# ESP32S31_RADIO register map
Vendor: Espressif; Series: ESP32-S31; File version: 3.52
Registers are 32-bit, read-write, no defined reset value unless marked. A register's access mark holds for its fields unless they carry their own. Offsets are from the block's base; [hi:lo] are bit positions; {n}, {i} and the like mark numbered series.

## SYSTIMER — The system timer's comparators: their enables in CONF, targets, modes, load strobes and interrupt enables; their acknowledgements are SYSTIMER_ACKNOWLEDGE. The counter latch of unit zero is the separate shared block SYSTIMER_COUNTER; unit one, the unit loads and the read-back registers are not described.
Base 0x20399000
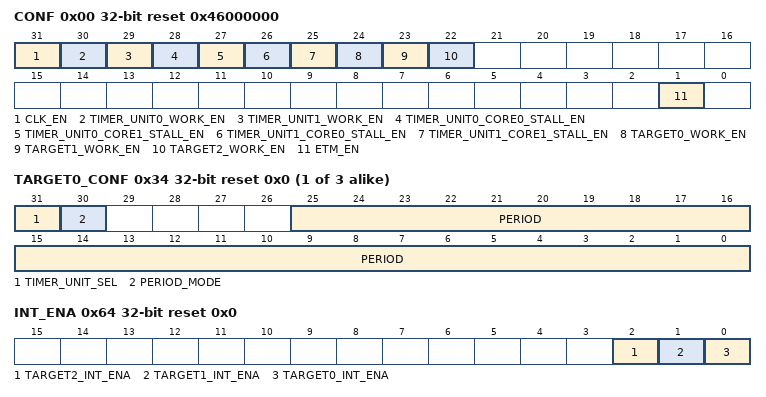
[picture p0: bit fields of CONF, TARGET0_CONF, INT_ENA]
0x00 CONF reset 0x46000000 — Project-assigned name. Clock, unit and comparator enables.
  [31] CLK_EN — Project-assigned name. Keeps the register clock enabled for every access.
  [30] TIMER_UNIT0_WORK_EN — Project-assigned name. Enables unit 0.
  [29] TIMER_UNIT1_WORK_EN — Project-assigned name. Enables unit 1.
  [28] TIMER_UNIT0_CORE0_STALL_EN — Project-assigned name. Stalls unit 0 while core 0 is stalled.
  [27] TIMER_UNIT0_CORE1_STALL_EN — Project-assigned name. Stalls unit 0 while core 1 is stalled.
  [26] TIMER_UNIT1_CORE0_STALL_EN — Project-assigned name. Stalls unit 1 while core 0 is stalled.
  [25] TIMER_UNIT1_CORE1_STALL_EN — Project-assigned name. Stalls unit 1 while core 1 is stalled.
  [24] TARGET0_WORK_EN — Project-assigned name. Enables comparator 0.
  [23] TARGET1_WORK_EN — Project-assigned name. Enables comparator 1.
  [22] TARGET2_WORK_EN — Project-assigned name. Enables comparator 2.
  [1] ETM_EN — Project-assigned name. Enables the generation of ETM events.
{0x1C+8i} TARGET{i}_HI (i=0..2) reset 0x0 — Project-assigned name. High 20 bits of comparator {i}'s alarm target.
  [19:0] HI — Project-assigned name. Target bits 51:32.
{0x20+8i} TARGET{i}_LO (i=0..2) reset 0x0 — Project-assigned name. Low 32 bits of comparator {i}'s alarm target.
  [31:0] LO — Project-assigned name. Target bits 31:0.
{0x34+4i} TARGET{i}_CONF (i=0..2) reset 0x0 — Project-assigned name. Alarm mode of comparator {i}.
  [31] TIMER_UNIT_SEL — Project-assigned name. Selects unit 1 instead of unit 0 as the compared counter.
  [30] PERIOD_MODE — Project-assigned name. Selects period mode instead of one-shot target mode.
  [25:0] PERIOD — Project-assigned name. Alarm period in period mode.
{0x50+4i} COMP{i}_LOAD (i=0..2) wo reset 0x0 — Project-assigned name. Load strobe of comparator {i}: writing one loads its target and mode.
  [0] LOAD — Project-assigned name. Loads the comparator's target and mode.
0x64 INT_ENA reset 0x0 — Project-assigned name. Comparator interrupt enables.
  [2] TARGET2_INT_ENA — Project-assigned name. Enables comparator 2's interrupt.
  [1] TARGET1_INT_ENA — Project-assigned name. Enables comparator 1's interrupt.
  [0] TARGET0_INT_ENA — Project-assigned name. Enables comparator 0's interrupt.

## SYSTIMER_COUNTER — The counter latch of system timer unit zero: the UPDATE strobe copies the counter into VALUE_HI and VALUE_LO and VALUE_VALID reports the copy done. Every context reads the counter, so this is a shared block: a strobe writes UPDATE alone and the values are read without a side effect.
Base 0x20399004
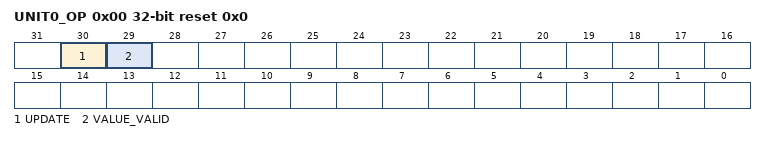
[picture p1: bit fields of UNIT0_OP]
0x00 UNIT0_OP reset 0x0 — Project-assigned name. Unit zero's latch strobe and its done flag.
  [30] UPDATE wo — Project-assigned name. Writing one latches unit zero's count into VALUE_HI and VALUE_LO.
  [29] VALUE_VALID ro — Project-assigned name. Set when the latched value is synchronized and valid (R/SS/WTC: a written one clears it, so the strobe writes zero here).
0x3C UNIT0_VALUE_HI ro reset 0x0 — Project-assigned name. High 20 bits of unit zero's latched count.
  [19:0] VALUE_HI — Project-assigned name. Count bits 51:32.
0x40 UNIT0_VALUE_LO ro reset 0x0 — Project-assigned name. Low 32 bits of unit zero's latched count.
  [31:0] VALUE_LO — Project-assigned name. Count bits 31:0.

## SYSTIMER_ACKNOWLEDGE — The comparators' interrupt acknowledgements. Each comparator's alarm handler strobes its own bit alone, from its own context, so this is a shared block of write-trigger strobes.
Base 0x2039906C
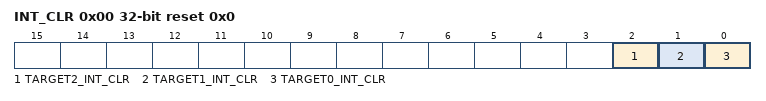
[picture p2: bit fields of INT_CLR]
0x00 INT_CLR wo reset 0x0 write-1-clears — Project-assigned name. Comparator interrupt acknowledgements: a written one clears the raw bit.
  [2] TARGET2_INT_CLR — Project-assigned name. Clears comparator 2's interrupt.
  [1] TARGET1_INT_CLR — Project-assigned name. Clears comparator 1's interrupt.
  [0] TARGET0_INT_CLR — Project-assigned name. Clears comparator 0's interrupt.
